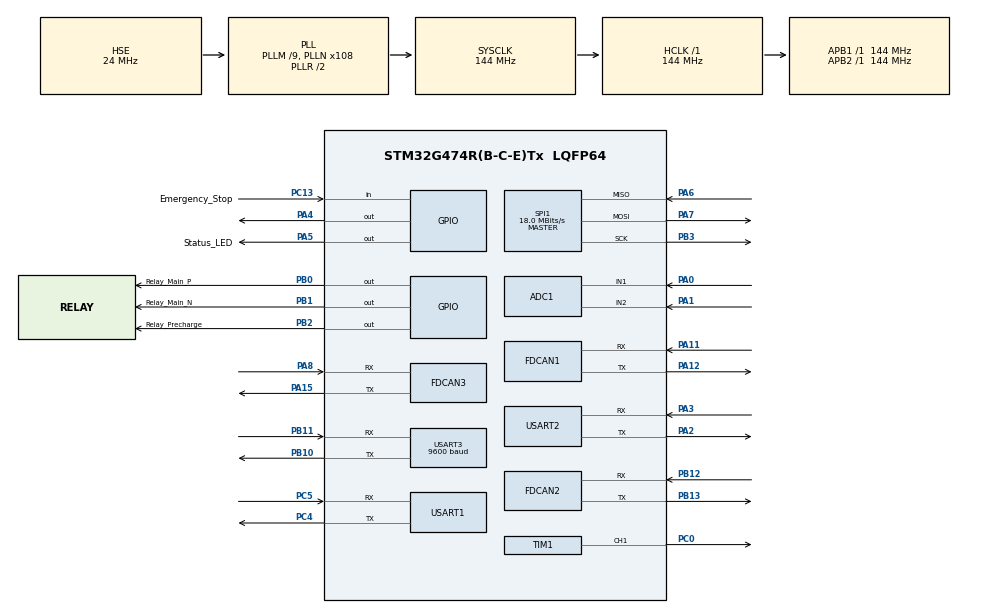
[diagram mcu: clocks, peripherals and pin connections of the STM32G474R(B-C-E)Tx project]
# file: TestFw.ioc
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ADC1.Channel-0\#ChannelRegularConversion=ADC_CHANNEL_1
ADC1.NbrOfConversionFlag=1
ADC1.OffsetNumber-0\#ChannelRegularConversion=ADC_OFFSET_NONE
ADC1.Rank-0\#ChannelRegularConversion=1
ADC1.SamplingTime-0\#ChannelRegularConversion=ADC_SAMPLETIME_2CYCLES_5
ADC1.master=1
Dma.Request0=USART2_TX
Dma.Request1=USART3_RX
Dma.Request2=USART3_TX
Dma.USART2_TX.0.Direction=DMA_MEMORY_TO_PERIPH
Dma.USART2_TX.0.EventEnable=DISABLE
Dma.USART2_TX.0.Instance=DMA1_Channel1
Dma.USART2_TX.0.MemDataAlignment=DMA_MDATAALIGN_BYTE
Dma.USART2_TX.0.MemInc=DMA_MINC_ENABLE
Dma.USART2_TX.0.Mode=DMA_NORMAL
Dma.USART2_TX.0.PeriphDataAlignment=DMA_PDATAALIGN_BYTE
Dma.USART2_TX.0.PeriphInc=DMA_PINC_DISABLE
Dma.USART2_TX.0.Polarity=HAL_DMAMUX_REQ_GEN_RISING
Dma.USART2_TX.0.Priority=DMA_PRIORITY_LOW
Dma.USART2_TX.0.RequestNumber=1
Dma.USART2_TX.0.SignalID=NONE
Dma.USART2_TX.0.SyncEnable=DISABLE
Dma.USART2_TX.0.SyncPolarity=HAL_DMAMUX_SYNC_NO_EVENT
Dma.USART2_TX.0.SyncRequestNumber=1
Dma.USART2_TX.0.SyncSignalID=NONE
Dma.USART3_RX.1.Direction=DMA_PERIPH_TO_MEMORY
Dma.USART3_RX.1.EventEnable=DISABLE
Dma.USART3_RX.1.Instance=DMA1_Channel2
Dma.USART3_RX.1.MemDataAlignment=DMA_MDATAALIGN_BYTE
Dma.USART3_RX.1.MemInc=DMA_MINC_ENABLE
Dma.USART3_RX.1.Mode=DMA_NORMAL
Dma.USART3_RX.1.PeriphDataAlignment=DMA_PDATAALIGN_BYTE
Dma.USART3_RX.1.PeriphInc=DMA_PINC_DISABLE
Dma.USART3_RX.1.Polarity=HAL_DMAMUX_REQ_GEN_RISING
Dma.USART3_RX.1.Priority=DMA_PRIORITY_LOW
Dma.USART3_RX.1.RequestNumber=1
Dma.USART3_RX.1.SignalID=NONE
Dma.USART3_RX.1.SyncEnable=DISABLE
Dma.USART3_RX.1.SyncPolarity=HAL_DMAMUX_SYNC_NO_EVENT
Dma.USART3_RX.1.SyncRequestNumber=1
Dma.USART3_RX.1.SyncSignalID=NONE
Dma.USART3_TX.2.Direction=DMA_MEMORY_TO_PERIPH
Dma.USART3_TX.2.EventEnable=DISABLE
Dma.USART3_TX.2.Instance=DMA1_Channel3
Dma.USART3_TX.2.MemDataAlignment=DMA_MDATAALIGN_BYTE
Dma.USART3_TX.2.MemInc=DMA_MINC_ENABLE
Dma.USART3_TX.2.Mode=DMA_NORMAL
Dma.USART3_TX.2.PeriphDataAlignment=DMA_PDATAALIGN_BYTE
Dma.USART3_TX.2.PeriphInc=DMA_PINC_DISABLE
Dma.USART3_TX.2.Polarity=HAL_DMAMUX_REQ_GEN_RISING
Dma.USART3_TX.2.Priority=DMA_PRIORITY_LOW
Dma.USART3_TX.2.RequestNumber=1
Dma.USART3_TX.2.SignalID=NONE
Dma.USART3_TX.2.SyncEnable=DISABLE
Dma.USART3_TX.2.SyncPolarity=HAL_DMAMUX_SYNC_NO_EVENT
Dma.USART3_TX.2.SyncRequestNumber=1
Dma.USART3_TX.2.SyncSignalID=NONE
FDCAN1.CalculateBaudRateNominal=500000
FDCAN1.CalculateTimeBitNominal=2000
FDCAN1.CalculateTimeQuantumNominal=111.11111111111111
FDCAN1.NominalPrescaler=16
FDCAN1.NominalTimeSeg1=14
FDCAN1.NominalTimeSeg2=3
FDCAN2.CalculateBaudRateNominal=125000
FDCAN2.CalculateTimeBitNominal=8000
FDCAN2.CalculateTimeQuantumNominal=444.44444444444446
FDCAN2.NominalPrescaler=64
FDCAN2.NominalTimeSeg1=14
FDCAN2.NominalTimeSeg2=3
FDCAN3.CalculateBaudRateNominal=500000
FDCAN3.CalculateTimeBitNominal=2000
FDCAN3.CalculateTimeQuantumNominal=111.11111111111111
FDCAN3.NominalPrescaler=16
FDCAN3.NominalTimeSeg1=14
FDCAN3.NominalTimeSeg2=3
FREERTOS.Tasks01=defaultTask,24,128,StartDefaultTask,Default,NULL,Dynamic,NULL,NULL
FREERTOS.configUSE_NEWLIB_REENTRANT=1
IWDG.Reload=1024
IWDG.Window=1024
Mcu.Family=STM32G4
Mcu.Name=STM32G474R(B-C-E)Tx
Mcu.Package=LQFP64
NVIC.DMA1_Channel1_IRQn=true\:5\:0\:false\:false\:true\:true\:false\:true\:true
NVIC.DMA1_Channel2_IRQn=true\:5\:0\:false\:false\:true\:true\:false\:true\:true
NVIC.DMA1_Channel3_IRQn=true\:5\:0\:false\:false\:true\:true\:false\:true\:true
NVIC.PriorityGroup=NVIC_PRIORITYGROUP_4
NVIC.TIM4_IRQn=true\:15\:0\:false\:false\:true\:false\:false\:true\:true
NVIC.TimeBase=TIM4_IRQn
NVIC.TimeBaseIP=TIM4
PA0.Mode=IN1-Single-Ended
PA0.Signal=ADC1_IN1
PA1.Mode=IN2-Single-Ended
PA1.Signal=ADC1_IN2
PA11.Mode=FDCAN_Activate
PA11.Signal=FDCAN1_RX
PA12.Mode=FDCAN_Activate
PA12.Signal=FDCAN1_TX
PA13.GPIO_Label=T_SWDIO
PA13.Mode=Serial_Wire
PA13.Signal=SYS_JTMS-SWDIO
PA14.GPIO_Label=T_SWCLK
PA14.Mode=Serial_Wire
PA14.Signal=SYS_JTCK-SWCLK
PA15.Mode=FDCAN_Activate
PA15.Signal=FDCAN3_TX
PA2.Mode=Asynchronous
PA2.Signal=USART2_TX
PA3.Mode=Asynchronous
PA3.Signal=USART2_RX
PA4.Signal=GPIO_Output
PA5.GPIO_Label=Status_LED
PA5.Signal=GPIO_Output
PA6.Mode=Full_Duplex_Master
PA6.Signal=SPI1_MISO
PA7.Mode=Full_Duplex_Master
PA7.Signal=SPI1_MOSI
PA8.Mode=FDCAN_Activate
PA8.Signal=FDCAN3_RX
PB0.GPIO_Label=Relay_Main_P
PB0.Signal=GPIO_Output
PB1.GPIO_Label=Relay_Main_N
PB1.Signal=GPIO_Output
PB10.Mode=Asynchronous
PB10.Signal=USART3_TX
PB11.Mode=Asynchronous
PB11.Signal=USART3_RX
PB12.Mode=FDCAN_Activate
PB12.Signal=FDCAN2_RX
PB13.Mode=FDCAN_Activate
PB13.Signal=FDCAN2_TX
PB2.GPIO_Label=Relay_Precharge
PB2.Signal=GPIO_Output
PB3.Mode=Full_Duplex_Master
PB3.Signal=SPI1_SCK
PC0.Signal=S_TIM1_CH1
PC13.GPIO_Label=Emergency_Stop
PC13.Signal=GPIO_Input
PC14-OSC32_IN.GPIO_Label=RCC_OSC32_IN
PC14-OSC32_IN.Mode=LSE-External-Oscillator
PC14-OSC32_IN.Signal=RCC_OSC32_IN
PC15-OSC32_OUT.GPIO_Label=RCC_OSC32_OUT
PC15-OSC32_OUT.Mode=LSE-External-Oscillator
PC15-OSC32_OUT.Signal=RCC_OSC32_OUT
PC4.Mode=Asynchronous
PC4.Signal=USART1_TX
PC5.Mode=Asynchronous
PC5.Signal=USART1_RX
PF0-OSC_IN.GPIO_Label=RCC_OSC_IN
PF0-OSC_IN.Mode=HSE-External-Oscillator
PF0-OSC_IN.Signal=RCC_OSC_IN
PF1-OSC_OUT.GPIO_Label=RCC_OSC_OUT
PF1-OSC_OUT.Mode=HSE-External-Oscillator
PF1-OSC_OUT.Signal=RCC_OSC_OUT
ProjectManager.HeapSize=0x200
ProjectManager.StackSize=0x400
ProjectManager.TargetToolchain=STM32CubeIDE
RCC.ADC12Freq_Value=144000000
RCC.ADC345Freq_Value=144000000
RCC.AHBFreq_Value=144000000
RCC.APB1Freq_Value=144000000
RCC.APB1TimFreq_Value=144000000
RCC.APB2Freq_Value=144000000
RCC.APB2TimFreq_Value=144000000
RCC.CortexFreq_Value=144000000
RCC.EXTERNAL_CLOCK_VALUE=12288000
RCC.HCLKFreq_Value=144000000
RCC.HSE_VALUE=24000000
RCC.HSI48_VALUE=48000000
RCC.HSI_VALUE=16000000
RCC.PLLM=RCC_PLLM_DIV9
RCC.PLLN=108
RCC.PLLQ=RCC_PLLQ_DIV6
RCC.PLLSourceVirtual=RCC_PLLSOURCE_HSE
RCC.RTCClockSelection=RCC_RTCCLKSOURCE_LSE
RCC.SYSCLKFreq_VALUE=144000000
RCC.SYSCLKSource=RCC_SYSCLKSOURCE_PLLCLK
RCC.USBFreq_Value=48000000
RCC.VCOOutputFreq_Value=288000000
SH.S_TIM1_CH1.0=TIM1_CH1,Output Compare1 CH1
SPI1.BaudRatePrescaler=SPI_BAUDRATEPRESCALER_8
SPI1.CalculateBaudRate=18.0 MBits/s
SPI1.DataSize=SPI_DATASIZE_8BIT
SPI1.Direction=SPI_DIRECTION_2LINES
SPI1.Mode=SPI_MODE_MASTER
SPI1.VirtualType=VM_MASTER
TIM1.Channel-Output\ Compare1\ CH1=TIM_CHANNEL_1
USART1.VirtualMode-Asynchronous=VM_ASYNC
USART2.VirtualMode-Asynchronous=VM_ASYNC
USART3.BaudRate=9600
USART3.VirtualMode-Asynchronous=VM_ASYNC
VP_FREERTOS_VS_CMSIS_V2.Mode=CMSIS_V2
VP_IWDG_VS_IWDG.Mode=IWDG_Activate
VP_RNG_VS_RNG.Mode=RNG_Activate
VP_SYS_VS_DBSignals.Mode=DisableDeadBatterySignals
VP_SYS_VS_tim4.Mode=TIM4
board=NUCLEO-G474RE

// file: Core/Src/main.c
/* USER CODE BEGIN Header */
/**
  ******************************************************************************
  * @file           : main.c
  * @brief          : Main program body
  ******************************************************************************
  * @attention
  *
  * Copyright (c) 2026 STMicroelectronics.
  * All rights reserved.
  *
  * This software is licensed under terms that can be found in the LICENSE file
  * in the root directory of this software component.
  * If no LICENSE file comes with this software, it is provided AS-IS.
  *
  ******************************************************************************
  */
/* USER CODE END Header */
#include "main.h"
#include "cmsis_os.h"
#include "adc.h"
#include "dma.h"
#include "fdcan.h"
#include "iwdg.h"
#include "rng.h"
#include "spi.h"
#include "tim.h"
#include "usart.h"
#include "gpio.h"

/* USER CODE BEGIN Includes */
#include "meter_driver.h"
#include "uart_driver.h"
/* USER CODE END Includes */

#include "logger.h"

void SystemClock_Config(void);
void MX_FREERTOS_Init(void);

int main(void)
{

  /* MCU Configuration--------------------------------------------------------*/

  /* Reset of all peripherals, Initializes the Flash interface and the Systick. */
  HAL_Init();

  /* Configure the system clock */
  SystemClock_Config();

  /* Initialize all configured peripherals */
  MX_GPIO_Init();
  MX_DMA_Init();
  MX_ADC1_Init();
  MX_FDCAN1_Init();
  MX_FDCAN2_Init();
  MX_TIM1_Init();
  MX_USART1_UART_Init();
  MX_USART2_UART_Init();
  MX_USART3_UART_Init();
  MX_FDCAN3_Init();
  MX_RNG_Init();
  MX_SPI1_Init();
  MX_IWDG_Init();
  /* USER CODE BEGIN 2 */
  Logger_Init();
  /* USER CODE END 2 */

  /* Init scheduler */
  osKernelInitialize();  /* Call init function for freertos objects (in cmsis_os2.c) */
  MX_FREERTOS_Init();

  /* Start scheduler */
  osKernelStart();

  /* We should never get here as control is now taken by the scheduler */

  /* Infinite loop */
  while (1)
  {

  }
}

void SystemClock_Config(void)
{
  RCC_OscInitTypeDef RCC_OscInitStruct = {0};
  RCC_ClkInitTypeDef RCC_ClkInitStruct = {0};

  /** Configure the main internal regulator output voltage
  */
  HAL_PWREx_ControlVoltageScaling(PWR_REGULATOR_VOLTAGE_SCALE1);

  /** Initializes the RCC Oscillators according to the specified parameters
  * in the RCC_OscInitTypeDef structure.
  */
  RCC_OscInitStruct.OscillatorType = RCC_OSCILLATORTYPE_LSI|RCC_OSCILLATORTYPE_HSE;
  RCC_OscInitStruct.HSEState = RCC_HSE_ON;
  RCC_OscInitStruct.LSIState = RCC_LSI_ON;
  RCC_OscInitStruct.PLL.PLLState = RCC_PLL_ON;
  RCC_OscInitStruct.PLL.PLLSource = RCC_PLLSOURCE_HSE;
  RCC_OscInitStruct.PLL.PLLM = RCC_PLLM_DIV9;
  RCC_OscInitStruct.PLL.PLLN = 108;
  RCC_OscInitStruct.PLL.PLLP = RCC_PLLP_DIV2;
  RCC_OscInitStruct.PLL.PLLQ = RCC_PLLQ_DIV6;
  RCC_OscInitStruct.PLL.PLLR = RCC_PLLR_DIV2;
  if (HAL_RCC_OscConfig(&RCC_OscInitStruct) != HAL_OK)
  {
    Error_Handler();
  }

  /** Initializes the CPU, AHB and APB buses clocks
  */
  RCC_ClkInitStruct.ClockType = RCC_CLOCKTYPE_HCLK|RCC_CLOCKTYPE_SYSCLK
                              |RCC_CLOCKTYPE_PCLK1|RCC_CLOCKTYPE_PCLK2;
  RCC_ClkInitStruct.SYSCLKSource = RCC_SYSCLKSOURCE_PLLCLK;
  RCC_ClkInitStruct.AHBCLKDivider = RCC_SYSCLK_DIV1;
  RCC_ClkInitStruct.APB1CLKDivider = RCC_HCLK_DIV1;
  RCC_ClkInitStruct.APB2CLKDivider = RCC_HCLK_DIV1;

  if (HAL_RCC_ClockConfig(&RCC_ClkInitStruct, FLASH_LATENCY_4) != HAL_OK)
  {
    Error_Handler();
  }
}

/**
  * @brief  Tx Transfer completed callback
  * @param  huart: UART handle
  * @retval None
  */
void HAL_UART_TxCpltCallback(UART_HandleTypeDef *huart)
{
  Logger_TxCpltCallback(huart);
}

/**
  * @brief  Rx Transfer completed callback
  * @param  huart: UART handle
  * @retval None
  */
void HAL_UART_RxCpltCallback(UART_HandleTypeDef *huart)
{
  UART_CLI_RxCpltCallback(huart);
  Meter_RxCpltCallback(huart);
}

void HAL_TIM_PeriodElapsedCallback(TIM_HandleTypeDef *htim)
{
  if (htim->Instance == TIM4)
  {
    HAL_IncTick();
  }
}

void Error_Handler(void)
{
  __disable_irq();
  while (1)
  {
  }
}

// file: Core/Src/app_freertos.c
/* USER CODE BEGIN Header */
/**
  ******************************************************************************
  * File Name          : app_freertos.c
  * Description        : Code for freertos applications
  ******************************************************************************
  * @attention
  *
  * Copyright (c) 2026 STMicroelectronics.
  * All rights reserved.
  *
  * This software is licensed under terms that can be found in the LICENSE file
  * in the root directory of this software component.
  * If no LICENSE file comes with this software, it is provided AS-IS.
  *
  ******************************************************************************
  */
/* USER CODE END Header */

#include "FreeRTOS.h"
#include "task.h"
#include "main.h"
#include "cmsis_os.h"

/* USER CODE BEGIN Includes */
#include "app_main.h"
/* USER CODE END Includes */

/* Definitions for defaultTask (Control Task) */
osThreadId_t defaultTaskHandle;
const osThreadAttr_t defaultTask_attributes = {
  .name = "ControlTask", // Renamed for clarity
  .priority = (osPriority_t) osPriorityAboveNormal, // High Priority
  .stack_size = 128 * 4 // 512 Bytes
};

/* Definitions for OCPP Task */
osThreadId_t ocppTaskHandle;
const osThreadAttr_t ocppTask_attributes = {
  .name = "OCPP_Task",
  .priority = (osPriority_t) osPriorityNormal, // Normal Priority
  .stack_size = 512 * 4 // 2048 Bytes for TLS
};

void StartDefaultTask(void *argument);
void StartOCPPTask(void *argument); // New Prototype

void MX_FREERTOS_Init(void); /* (MISRA C 2004 rule 8.1) */

void MX_FREERTOS_Init(void) {

  /* Create the thread(s) */
  /* creation of defaultTask */
  defaultTaskHandle = osThreadNew(StartDefaultTask, NULL, &defaultTask_attributes);

  /* creation of OCPP Task */
  ocppTaskHandle = osThreadNew(StartOCPPTask, NULL, &ocppTask_attributes);

}

/* USER CODE BEGIN Header_StartDefaultTask */
/**
  * @brief  Function implementing the defaultTask (ControlTask) thread.
  * @param  argument: Not used
  * @retval None
  */
/* USER CODE END Header_StartDefaultTask */
void StartDefaultTask(void *argument)
{
  /* USER CODE BEGIN StartDefaultTask */

  // 1. Initialize Hardware & Modules (Once)
  App_Init();

  // 2. Run High Priority Control Loop (Safety, State Machine)
  App_ControlLoop();

  // Should not reach here
  for(;;)
  {
    osDelay(1);
  }
  /* USER CODE END StartDefaultTask */
}

/* New OCPP Task Entry */
void StartOCPPTask(void *argument)
{
    // Wait for Init to largely complete (optional sync, or just rely on OS start order/delay)
    osDelay(100);

    // Run OCPP Loop (Blocking allowed here)
    App_OCPPLoop();

    for(;;)
    {
        osDelay(1);
    }
}
